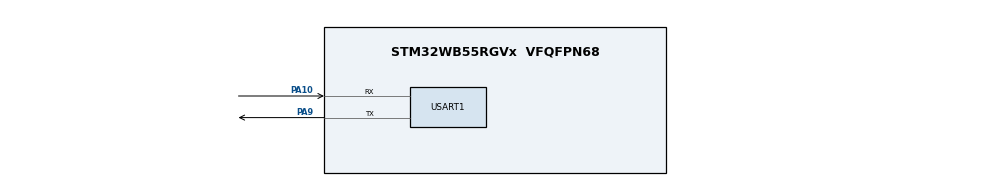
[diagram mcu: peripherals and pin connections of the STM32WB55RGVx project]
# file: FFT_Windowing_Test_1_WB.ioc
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Mcu.Family=STM32WB
Mcu.Name=STM32WB55RGVx
Mcu.Package=VFQFPN68
NVIC.PriorityGroup=NVIC_PRIORITYGROUP_4
PA10.Mode=Asynchronous
PA10.Signal=USART1_RX
PA9.Mode=Asynchronous
PA9.Signal=USART1_TX
ProjectManager.HeapSize=0x200
ProjectManager.StackSize=0x400
ProjectManager.TargetToolchain=STM32CubeIDE
RCC.AHBFreq_Value=32000000
RCC.APB1Freq_Value=32000000
RCC.APB1TimFreq_Value=32000000
RCC.APB2Freq_Value=32000000
RCC.APB2TimFreq_Value=32000000
RCC.APB3Freq_Value=16000000
RCC.CortexFreq_Value=32000000
RCC.HCLKFreq_Value=32000000
RCC.HSE_VALUE=8000000
RCC.HSI48_VALUE=48000000
RCC.HSI_VALUE=16000000
RCC.LSE_VALUE=32768
RCC.PLLN=24
RCC.PLLR=RCC_PLLR_DIV3
RCC.SYSCLKFreq_VALUE=32000000
RCC.SYSCLKSource=RCC_SYSCLKSOURCE_PLLCLK
RCC.VCOOutputFreq_Value=96000000
STMicroelectronics.X-CUBE-ALGOBUILD.1.4.0.LibraryCcDSPOoLibraryJjDSPOoLibrary=true
USART1.VirtualMode-Asynchronous=VM_ASYNC
VP_MEMORYMAP_VS_MEMORYMAP.Mode=CurAppReg
VP_STMicroelectronics.X-CUBE-ALGOBUILD_VS_DSPOoLibraryJjLibrary_1.4.0_1.4.0.Mode=DSPOoLibraryJjLibrary
board=custom

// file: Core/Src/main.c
/* USER CODE BEGIN Header */
/**
  ******************************************************************************
  * @file           : main.c
  * @brief          : Main program body
  ******************************************************************************
  * @attention
  *
  * Copyright (c) 2024 STMicroelectronics.
  * All rights reserved.
  *
  * This software is licensed under terms that can be found in the LICENSE file
  * in the root directory of this software component.
  * If no LICENSE file comes with this software, it is provided AS-IS.
  *
  ******************************************************************************
  */
/* USER CODE END Header */
#include "main.h"

/* USER CODE BEGIN Includes */
#include "arm_math.h"
#include "string.h"
/* USER CODE END Includes */

UART_HandleTypeDef huart1;

/* USER CODE BEGIN PV */
#define UART_BUFFER_SIZE 2048
#define FFT_SIZE 1024

uint8_t uart_buffer[UART_BUFFER_SIZE];
float32_t input_data[FFT_SIZE];
float32_t fft_output[FFT_SIZE];
float32_t fft_magnitude[FFT_SIZE / 2];
float32_t window[FFT_SIZE]; // Hanning window
arm_rfft_fast_instance_f32 fft_instance;
/* USER CODE END PV */

void SystemClock_Config(void);
void PeriphCommonClock_Config(void);
static void MX_GPIO_Init(void);
static void MX_USART1_UART_Init(void);

/* USER CODE BEGIN 0 */
void apply_window(float32_t *data, float32_t *window, uint32_t size);
void process_wav_fft(void);
/* USER CODE END 0 */

int main(void)
{

  /* MCU Configuration--------------------------------------------------------*/

  /* Reset of all peripherals, Initializes the Flash interface and the Systick. */
  HAL_Init();

  /* Configure the system clock */
  SystemClock_Config();

/* Configure the peripherals common clocks */
  PeriphCommonClock_Config();

  /* Initialize all configured peripherals */
  MX_GPIO_Init();
  MX_USART1_UART_Init();
  /* USER CODE BEGIN 2 */
  // Initialize the FFT instance
      arm_rfft_fast_init_f32(&fft_instance, FFT_SIZE);

      // Generate Hanning window manually
       for (int i = 0; i < FFT_SIZE; i++) {
      	 window[i] = 0.5f * (1.0f - arm_cos_f32((2.0f * PI * i) / (FFT_SIZE - 1)));
       }
       // Generate Hanning window
       //arm_hann_window_f32(window, FFT_SIZE);

  /* USER CODE END 2 */

  /* Infinite loop */
  while (1)
  {

    /* USER CODE BEGIN 3 */
	  // Receive the .wav file data via UART
	          if (HAL_UART_Receive(&huart1, uart_buffer, UART_BUFFER_SIZE, HAL_MAX_DELAY) == HAL_OK)
	          {
	              // Convert received data to float32_t format (assumes 16-bit PCM data in .wav file)
	              for (int i = 0; i < FFT_SIZE; i++) {
	                  input_data[i] = (float32_t)((int16_t)(uart_buffer[2 * i] | (uart_buffer[2 * i + 1] << 8)));
	              }

	              // Apply the Hanning window to the input data
	              for (int i = 0; i < FFT_SIZE; i++) {
	              	input_data[i] *= window[i];
	              }
	              // Apply Hanning window to the input data
	              apply_window(input_data, window, FFT_SIZE);

	              // Perform FFT
	              arm_rfft_fast_f32(&fft_instance, input_data, fft_output, 0);

	              // Compute the magnitude of the FFT output
	              arm_cmplx_mag_f32(fft_output, fft_magnitude, FFT_SIZE / 2);

	              // Send FFT output via UART
	              HAL_UART_Transmit(&huart1, (uint8_t *)fft_magnitude, sizeof(fft_magnitude), HAL_MAX_DELAY);
	          }

  }
  /* USER CODE END 3 */
}

void apply_window(float32_t *data, float32_t *window, uint32_t size) {
    for (uint32_t i = 0; i < size; i++) {
        data[i] *= window[i];
    }
}

void SystemClock_Config(void)
{
  RCC_OscInitTypeDef RCC_OscInitStruct = {0};
  RCC_ClkInitTypeDef RCC_ClkInitStruct = {0};

  /** Configure the main internal regulator output voltage
  */
  __HAL_PWR_VOLTAGESCALING_CONFIG(PWR_REGULATOR_VOLTAGE_SCALE1);

  /** Initializes the RCC Oscillators according to the specified parameters
  * in the RCC_OscInitTypeDef structure.
  */
  RCC_OscInitStruct.OscillatorType = RCC_OSCILLATORTYPE_HSI|RCC_OSCILLATORTYPE_MSI;
  RCC_OscInitStruct.HSIState = RCC_HSI_ON;
  RCC_OscInitStruct.MSIState = RCC_MSI_ON;
  RCC_OscInitStruct.HSICalibrationValue = RCC_HSICALIBRATION_DEFAULT;
  RCC_OscInitStruct.MSICalibrationValue = RCC_MSICALIBRATION_DEFAULT;
  RCC_OscInitStruct.MSIClockRange = RCC_MSIRANGE_6;
  RCC_OscInitStruct.PLL.PLLState = RCC_PLL_ON;
  RCC_OscInitStruct.PLL.PLLSource = RCC_PLLSOURCE_MSI;
  RCC_OscInitStruct.PLL.PLLM = RCC_PLLM_DIV1;
  RCC_OscInitStruct.PLL.PLLN = 24;
  RCC_OscInitStruct.PLL.PLLP = RCC_PLLP_DIV2;
  RCC_OscInitStruct.PLL.PLLR = RCC_PLLR_DIV3;
  RCC_OscInitStruct.PLL.PLLQ = RCC_PLLQ_DIV2;
  if (HAL_RCC_OscConfig(&RCC_OscInitStruct) != HAL_OK)
  {
    Error_Handler();
  }

  /** Configure the SYSCLKSource, HCLK, PCLK1 and PCLK2 clocks dividers
  */
  RCC_ClkInitStruct.ClockType = RCC_CLOCKTYPE_HCLK4|RCC_CLOCKTYPE_HCLK2
                              |RCC_CLOCKTYPE_HCLK|RCC_CLOCKTYPE_SYSCLK
                              |RCC_CLOCKTYPE_PCLK1|RCC_CLOCKTYPE_PCLK2;
  RCC_ClkInitStruct.SYSCLKSource = RCC_SYSCLKSOURCE_PLLCLK;
  RCC_ClkInitStruct.AHBCLKDivider = RCC_SYSCLK_DIV1;
  RCC_ClkInitStruct.APB1CLKDivider = RCC_HCLK_DIV1;
  RCC_ClkInitStruct.APB2CLKDivider = RCC_HCLK_DIV1;
  RCC_ClkInitStruct.AHBCLK2Divider = RCC_SYSCLK_DIV1;
  RCC_ClkInitStruct.AHBCLK4Divider = RCC_SYSCLK_DIV1;

  if (HAL_RCC_ClockConfig(&RCC_ClkInitStruct, FLASH_LATENCY_1) != HAL_OK)
  {
    Error_Handler();
  }
}

void PeriphCommonClock_Config(void)
{
  RCC_PeriphCLKInitTypeDef PeriphClkInitStruct = {0};

  /** Initializes the peripherals clock
  */
  PeriphClkInitStruct.PeriphClockSelection = RCC_PERIPHCLK_SMPS;
  PeriphClkInitStruct.SmpsClockSelection = RCC_SMPSCLKSOURCE_HSI;
  PeriphClkInitStruct.SmpsDivSelection = RCC_SMPSCLKDIV_RANGE1;

  if (HAL_RCCEx_PeriphCLKConfig(&PeriphClkInitStruct) != HAL_OK)
  {
    Error_Handler();
  }
}

static void MX_USART1_UART_Init(void)
{

  huart1.Instance = USART1;
  huart1.Init.BaudRate = 115200;
  huart1.Init.WordLength = UART_WORDLENGTH_8B;
  huart1.Init.StopBits = UART_STOPBITS_1;
  huart1.Init.Parity = UART_PARITY_NONE;
  huart1.Init.Mode = UART_MODE_TX_RX;
  huart1.Init.HwFlowCtl = UART_HWCONTROL_NONE;
  huart1.Init.OverSampling = UART_OVERSAMPLING_16;
  huart1.Init.OneBitSampling = UART_ONE_BIT_SAMPLE_DISABLE;
  huart1.Init.ClockPrescaler = UART_PRESCALER_DIV1;
  huart1.AdvancedInit.AdvFeatureInit = UART_ADVFEATURE_NO_INIT;
  if (HAL_UART_Init(&huart1) != HAL_OK)
  {
    Error_Handler();
  }
  if (HAL_UARTEx_SetTxFifoThreshold(&huart1, UART_TXFIFO_THRESHOLD_1_8) != HAL_OK)
  {
    Error_Handler();
  }
  if (HAL_UARTEx_SetRxFifoThreshold(&huart1, UART_RXFIFO_THRESHOLD_1_8) != HAL_OK)
  {
    Error_Handler();
  }
  if (HAL_UARTEx_DisableFifoMode(&huart1) != HAL_OK)
  {
    Error_Handler();
  }

}

static void MX_GPIO_Init(void)
{

  /* GPIO Ports Clock Enable */
  __HAL_RCC_GPIOA_CLK_ENABLE();

}

void Error_Handler(void)
{
  __disable_irq();
  while (1)
  {
  }
}
